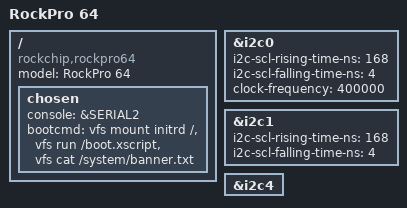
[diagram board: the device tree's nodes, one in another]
/**
 * Copyright (c) 2019 PT Switch.
 * All rights reserved.
 *
 * This program is free software; you can redistribute it and/or modify
 * it under the terms of the GNU General Public License as published by
 * the Free Software Foundation; either version 2, or (at your option)
 * any later version.
 *
 * This program is distributed in the hope that it will be useful,
 * but WITHOUT ANY WARRANTY; without even the implied warranty of
 * MERCHANTABILITY or FITNESS FOR A PARTICULAR PURPOSE.  See the
 * GNU General Public License for more details.
 *
 * You should have received a copy of the GNU General Public License
 * along with this program; if not, write to the Free Software
 * Foundation, Inc., 675 Mass Ave, Cambridge, MA 02139, USA.
 *
 * @file rockpro64.dts
 * @author Andy Dean (acd@kynesim.co.uk)
 * @brief ROckpro64 EVB device tree
 */


/dts-v1/;

/memreserve/ 0x00200000 0x00008000;

#include "rk3399.dtsi"

/ {
	compatible = "rockchip,rockpro64", "rockchip,rk3399";
	model = "RockPro 64";

	chosen {
		console = &SERIAL2;
		bootcmd = /* Mount initrd device */
			"vfs mount initrd /",

			/* Run boot script */
			"vfs run /boot.xscript",

			/* Print banner */
			"vfs cat /system/banner.txt";
	};
};

&i2c0 {
	status = "okay";
	i2c-scl-rising-time-ns = <168>;
	i2c-scl-falling-time-ns = <4>;
	clock-frequency = <400000>;

};

&i2c1 {
	status = "okay";
	i2c-scl-rising-time-ns = <168>;
	i2c-scl-falling-time-ns = <4>;
};

&i2c4 {
	status = "okay";
};

